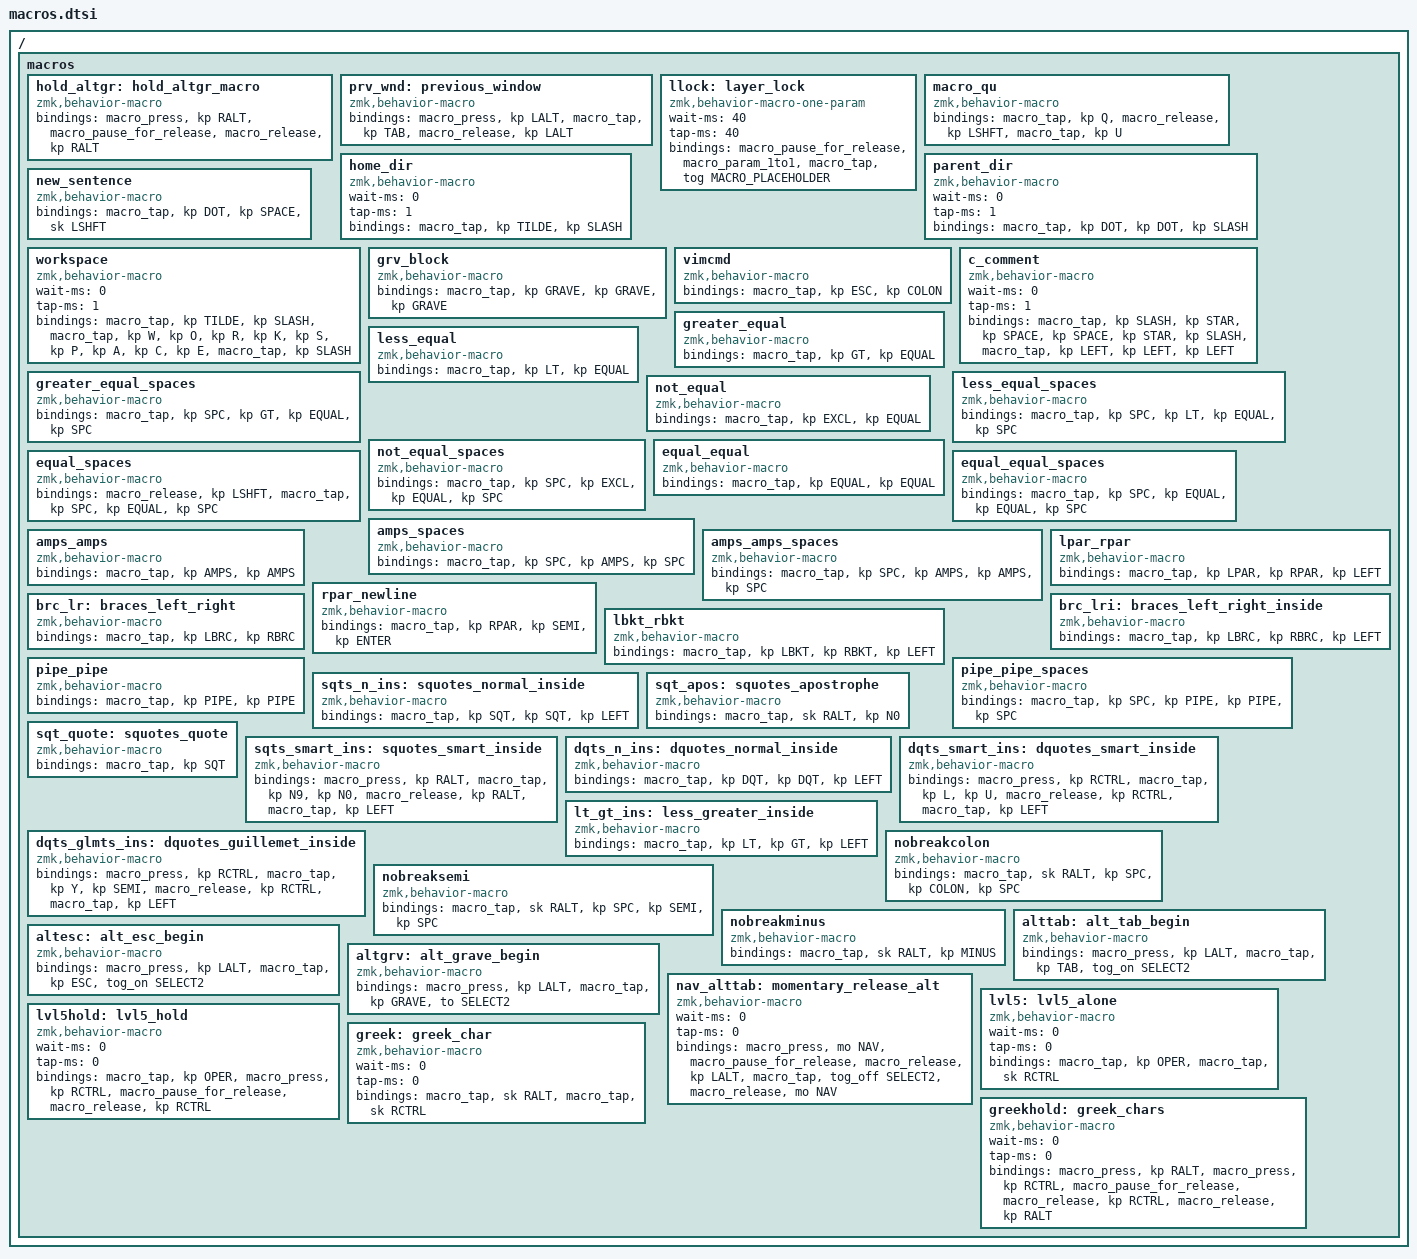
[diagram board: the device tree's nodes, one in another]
/* Generic macros */


/ {
    macros {
        // Hold AltGr after a tap-and-hold
        hold_altgr: hold_altgr_macro {
            compatible = "zmk,behavior-macro";
            #binding-cells = <0>;
            bindings = 
                <&macro_press &kp RALT>,
                <&macro_pause_for_release>,
                <&macro_release &kp RALT>;
        };

        // Single Alt-tab to swap to the previous window instead of cycling through
        prv_wnd: previous_window {
            compatible = "zmk,behavior-macro";
            #binding-cells = <0>;
            bindings = 
                <&macro_press &kp LALT>,
                <&macro_tap &kp TAB>,
                <&macro_release &kp LALT>;
        };
        // Layer lock, sort-of
        llock: layer_lock {
            compatible = "zmk,behavior-macro-one-param";
            #binding-cells = <1>;
            wait-ms = <40>;
            tap-ms = <40>;
            bindings =
                <&macro_pause_for_release>,
                <&macro_param_1to1>,
                <&macro_tap &tog MACRO_PLACEHOLDER>;
        };
        macro_qu: macro_qu {
            compatible = "zmk,behavior-macro";
            #binding-cells = <0>;
            bindings
                = <&macro_tap &kp Q>
                , <&macro_release &kp LSHFT>
                , <&macro_tap &kp U>
                ;
        };
        parent_dir: parent_dir {
            compatible = "zmk,behavior-macro";
            #binding-cells = <0>;
            wait-ms = <0>;
            tap-ms = <1>;
            bindings = <&macro_tap &kp DOT &kp DOT &kp SLASH>;
        };
        home_dir: home_dir {
            compatible = "zmk,behavior-macro";
            #binding-cells = <0>;
            wait-ms = <0>;
            tap-ms = <1>;
            bindings = <&macro_tap &kp TILDE &kp SLASH>;
        };
        new_sentence: new_sentence {
            compatible = "zmk,behavior-macro";
            #binding-cells = <0>;
            bindings
                = <&macro_tap &kp DOT &kp SPACE>
                , <&sk LSHFT>
                ;
        };
        workspace: workspace {
            compatible = "zmk,behavior-macro";
            #binding-cells = <0>;
            wait-ms = <0>;
            tap-ms = <1>;
            bindings
                = <&macro_tap &kp TILDE &kp SLASH>
                , <&macro_tap &kp W &kp O &kp R &kp K &kp S &kp P &kp A &kp C &kp E>
                , <&macro_tap &kp SLASH>
                ;
        };
        grv_block: grv_block {
            compatible = "zmk,behavior-macro";
            #binding-cells = <0>;
            bindings = <&macro_tap &kp GRAVE &kp GRAVE &kp GRAVE>;
        };
        vimcmd: vimcmd {
            compatible = "zmk,behavior-macro";
            #binding-cells = <0>;
            bindings = <&macro_tap &kp ESC &kp COLON>;
        };
        // Symbols macros
        c_comment: c_comment {
            compatible = "zmk,behavior-macro";
            #binding-cells = <0>;
            wait-ms = <0>;
            tap-ms = <1>;
            bindings
                = <&macro_tap &kp SLASH &kp STAR &kp SPACE &kp SPACE &kp STAR &kp SLASH>
                , <&macro_tap &kp LEFT &kp LEFT &kp LEFT>
                ;
        };
        greater_equal: greater_equal {
            compatible = "zmk,behavior-macro";
            #binding-cells = <0>;
            bindings = <&macro_tap &kp GT &kp EQUAL>;
        };
        greater_equal_spaces: greater_equal_spaces {
            compatible = "zmk,behavior-macro";
            #binding-cells = <0>;
            bindings = <&macro_tap  &kp SPC &kp GT &kp EQUAL &kp SPC>;
        };
        less_equal: less_equal {
            compatible = "zmk,behavior-macro";
            #binding-cells = <0>;
            bindings = <&macro_tap &kp LT &kp EQUAL>;
        };
        less_equal_spaces: less_equal_spaces {
            compatible = "zmk,behavior-macro";
            #binding-cells = <0>;
            bindings = <&macro_tap &kp SPC &kp LT &kp EQUAL &kp SPC>;
        };
        not_equal: not_equal {
            compatible = "zmk,behavior-macro";
            #binding-cells = <0>;
            bindings = <&macro_tap &kp EXCL &kp EQUAL>;
        };
        not_equal_spaces: not_equal_spaces {
            compatible = "zmk,behavior-macro";
            #binding-cells = <0>;
            bindings = <&macro_tap &kp SPC &kp EXCL &kp EQUAL &kp SPC>;
        };
        equal_spaces: equal_spaces {
            compatible = "zmk,behavior-macro";
            #binding-cells = <0>;
            bindings = 
                <&macro_release &kp LSHFT>,
                <&macro_tap &kp SPC &kp EQUAL &kp SPC>;
        };
        equal_equal: equal_equal {
            compatible = "zmk,behavior-macro";
            #binding-cells = <0>;
            bindings = <&macro_tap &kp EQUAL &kp EQUAL>;
        };
        equal_equal_spaces: equal_equal_spaces {
            compatible = "zmk,behavior-macro";
            #binding-cells = <0>;
            bindings = <&macro_tap &kp SPC &kp EQUAL &kp EQUAL &kp SPC>;
        };
        amps_spaces: amps_spaces {
            compatible = "zmk,behavior-macro";
            #binding-cells = <0>;
            bindings = <&macro_tap &kp SPC &kp AMPS &kp SPC>;
        };
        amps_amps: amps_amps {
            compatible = "zmk,behavior-macro";
            #binding-cells = <0>;
            bindings = <&macro_tap &kp AMPS &kp AMPS>;
        };
        amps_amps_spaces: amps_amps_spaces {
            compatible = "zmk,behavior-macro";
            #binding-cells = <0>;
            bindings = <&macro_tap &kp SPC &kp AMPS &kp AMPS &kp SPC>;
        };
        lpar_rpar: lpar_rpar {
            compatible = "zmk,behavior-macro";
            #binding-cells = <0>;
            bindings = <&macro_tap &kp LPAR &kp RPAR &kp LEFT>;
        };
        rpar_newline: rpar_newline {
            compatible = "zmk,behavior-macro";
            #binding-cells = <0>;
            bindings = <&macro_tap &kp RPAR &kp SEMI &kp ENTER>;
        };
        brc_lri: braces_left_right_inside {
            compatible = "zmk,behavior-macro";
            #binding-cells = <0>;
            bindings = <&macro_tap &kp LBRC &kp RBRC &kp LEFT>;
        };
        brc_lr: braces_left_right {
            compatible = "zmk,behavior-macro";
            #binding-cells = <0>;
            bindings = <&macro_tap &kp LBRC &kp RBRC>;
        };
        lbkt_rbkt: lbkt_rbkt {
            compatible = "zmk,behavior-macro";
            #binding-cells = <0>;
            bindings = <&macro_tap &kp LBKT &kp RBKT &kp LEFT>;
        };
        pipe_pipe: pipe_pipe {
            compatible = "zmk,behavior-macro";
            #binding-cells = <0>;
            bindings = <&macro_tap &kp PIPE &kp PIPE>;
        };
        pipe_pipe_spaces: pipe_pipe_spaces {
            compatible = "zmk,behavior-macro";
            #binding-cells = <0>;
            bindings = <&macro_tap &kp SPC &kp PIPE &kp PIPE &kp SPC>;
        };
        sqts_n_ins: squotes_normal_inside {
            compatible = "zmk,behavior-macro";
            #binding-cells = <0>;
            bindings = <&macro_tap &kp SQT &kp SQT &kp LEFT>;
        };
        sqt_apos: squotes_apostrophe {
            compatible = "zmk,behavior-macro";
            #binding-cells = <0>;
            bindings =
                    <&macro_tap &sk RALT &kp N0>;
        };
        sqt_quote: squotes_quote {
            compatible = "zmk,behavior-macro";
            #binding-cells = <0>;
            bindings =
                    <&macro_tap &kp SQT>;
        };
        // requires custom XKB keymap
        sqts_smart_ins: squotes_smart_inside {
            compatible = "zmk,behavior-macro";
            #binding-cells = <0>;
            bindings =
                    <&macro_press &kp RALT>,
                    <&macro_tap &kp N9 &kp N0>,
                    <&macro_release &kp RALT>,
                    <&macro_tap &kp LEFT>;
        };
        dqts_n_ins: dquotes_normal_inside {
            compatible = "zmk,behavior-macro";
            #binding-cells = <0>;
            bindings = <&macro_tap &kp DQT &kp DQT &kp LEFT>;
        };
        // requires custom XKB keymap
        dqts_smart_ins: dquotes_smart_inside {
            compatible = "zmk,behavior-macro";
            #binding-cells = <0>;
            bindings =
                    <&macro_press &kp RCTRL>,
                    <&macro_tap &kp L &kp U>,
                    <&macro_release &kp RCTRL>,
                    <&macro_tap &kp LEFT>;
        };
        // requires custom XKB keymap
        dqts_glmts_ins: dquotes_guillemet_inside {
            compatible = "zmk,behavior-macro";
            #binding-cells = <0>;
            bindings =
                    <&macro_press &kp RCTRL>,
                    <&macro_tap &kp Y &kp SEMI>,
                    <&macro_release &kp RCTRL>,
                    <&macro_tap &kp LEFT>;
        };
        lt_gt_ins: less_greater_inside {
            compatible = "zmk,behavior-macro";
            #binding-cells = <0>;
            bindings = <&macro_tap &kp LT &kp GT &kp LEFT>;
        };

        nobreakcolon: nobreakcolon {
            compatible = "zmk,behavior-macro";
            #binding-cells = <0>;
            bindings = <&macro_tap &sk RALT &kp SPC &kp COLON &kp SPC>;
        };
        nobreaksemi: nobreaksemi {
            compatible = "zmk,behavior-macro";
            #binding-cells = <0>;
            bindings = <&macro_tap &sk RALT &kp SPC &kp SEMI &kp SPC>;
        };
        nobreakminus: nobreakminus {
            compatible = "zmk,behavior-macro";
            #binding-cells = <0>;
            bindings = <&macro_tap &sk RALT &kp MINUS>;
        };

        // Alt-tab simulation
        alttab: alt_tab_begin {
                compatible = "zmk,behavior-macro";
                #binding-cells = <0>;
                bindings =
                    <&macro_press &kp LALT>,
                    <&macro_tap &kp TAB &tog_on SELECT2>;
         };
        // Alt-esc simulation
        altesc: alt_esc_begin {
                compatible = "zmk,behavior-macro";
                #binding-cells = <0>;
                bindings =
                    <&macro_press &kp LALT>,
                    <&macro_tap &kp ESC &tog_on SELECT2>;
         };
        // Alt-grave simulation
        altgrv: alt_grave_begin {
                compatible = "zmk,behavior-macro";
                #binding-cells = <0>;
                bindings =
                    <&macro_press &kp LALT>,
                    <&macro_tap &kp GRAVE &to SELECT2>;
         };
        // macro to activate NAV, then release ALT and turn off the select2 layer
        nav_alttab: momentary_release_alt {
            compatible = "zmk,behavior-macro";
            #binding-cells = <0>;
            wait-ms = <0>;
            tap-ms = <0>;
            bindings = <&macro_press &mo NAV>
                     , <&macro_pause_for_release>
                     , <&macro_release &kp LALT>
                     , <&macro_tap &tog_off SELECT2>
                     , <&macro_release &mo NAV>
                     ;
        };

        // macro to deactivate AltGr with OPER used as a no-op key, then activate Lvl5
        lvl5: lvl5_alone {
            compatible = "zmk,behavior-macro";
            #binding-cells = <0>;
            wait-ms = <0>;
            tap-ms = <0>;
            bindings = <&macro_tap &kp OPER>
                     , <&macro_tap &sk RCTRL>;
        };
        // macro to deactivate AltGr with OPER used as a no-op key, then activate Lvl5 while key is held
        lvl5hold: lvl5_hold {
            compatible = "zmk,behavior-macro";
            #binding-cells = <0>;
            wait-ms = <0>;
            tap-ms = <0>;
            bindings = <&macro_tap &kp OPER>
                     , <&macro_press &kp RCTRL>
                     , <&macro_pause_for_release>
                     , <&macro_release &kp RCTRL>;
        };
        // macro for Greek char, reset timer on Lvl3 then activate Lvl5
        greek: greek_char {
            compatible = "zmk,behavior-macro";
            #binding-cells = <0>;
            wait-ms = <0>;
            tap-ms = <0>;
            bindings = <&macro_tap &sk RALT>
                     , <&macro_tap &sk RCTRL>;
        };
        greekhold: greek_chars {
            compatible = "zmk,behavior-macro";
            #binding-cells = <0>;
            wait-ms = <0>;
            tap-ms = <0>;
            bindings = <&macro_press &kp RALT>
                     , <&macro_press &kp RCTRL>
                     , <&macro_pause_for_release>
                     , <&macro_release &kp RCTRL>
                     , <&macro_release &kp RALT>;
        };

        
    };
};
